# STM32U3B5 register map
File version: 1.0
CPU: CM33 r0p1, little endian, MPU, FPU, 4 interrupt priority bits
Registers are 32-bit, read-write, reset 0x0 unless marked. A register's access mark holds for its fields unless they carry their own. Offsets are from the block's base; [hi:lo] are bit positions; {n}, {i} and the like mark numbered series; 'fields as' and 'values as' point back to an identical list.

## GPDMA1 (part 2 of 2)
Base 0x40020000
Same registers: SEC_GPDMA1 0x50020000
{0xA0+0x80*i} GPDMA_C{i}DAR (i=0..11) — GPDMA channel {i} destination address register
  [31:0] DA — This field is the pointer to the address from which the next data is written. During the channel activity, depending on the destination addressing mode (GPDMA_C{i}TR1.DINC), this field is kept fixed or incremented by the data width (GPDMA_C{i}TR1.DDW_LOG2[21:0]) after each burst destination data, reflecting the next address from which data is written. During the channel activity, this address is updated after each completed destination burst, consequently to: - the programmed destination burst; either in fixed addressing mode or in contiguous-data incremented mode. If contiguously incremented (GPDMA_C{i}TR1.DINC = 1), then the additional address offset value is the programmed burst size, as defined by GPDMA_C{i}TR1.DBL_1[5:0] and GPDMA_C{i}TR1.DDW_LOG2[1:0] - the additional destination incremented/decremented offset value as programmed by GPDMA_C{i}BR1.DDEC and GPDMA_CxTR3.DAO[12:0]. - once/if completed destination block transfer, for a channel {i} with 2D addressing capability (x=12to15), the additional block repeat destination incremented/decremented offset value as programmed by GPDMA_C{i}BR1.BRDDEC and GPDMA_CxBR2.BRDAO[15:0] In linked-list mode, after a LLI data transfer is completed, this register is automatically updated by the GPDMA from the memory, provided the LLI is set with GPDMA_C{i}LLR.UDA = 1. Note: A destination address must be aligned with the programmed data width of a destination burst (DA[2:0] versus GPDMA_C{i}TR1.DDW_LOG2[1:0]). Else, a user setting error is reported and no transfer is issued.
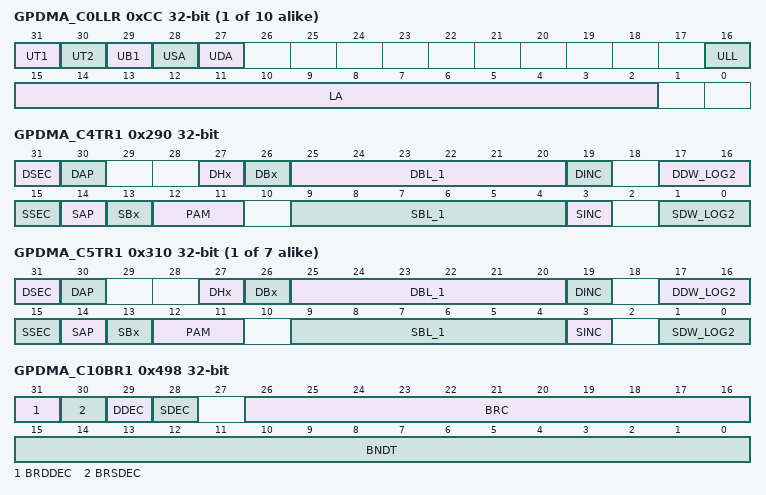
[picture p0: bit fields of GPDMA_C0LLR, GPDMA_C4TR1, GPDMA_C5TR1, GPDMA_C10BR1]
{0xCC+0x80*i} GPDMA_C{i}LLR (i=0..9) — GPDMA channel {i} linked-list address register
  [31] UT1 — This bit controls the update of GPDMA_C{i}TR1 from the memory during the link transfer. 0: no GPDMA_C{i}TR1 update 1: GPDMA_C{i}TR1 update
    0=no GPDMA_C{i}TR1 update; 1=GPDMA_C{i}TR1 update
  [30] UT2 — This bit controls the update of GPDMA_C{i}TR2 from the memory during the link transfer. 0: no GPDMA_C{i}TR2 update 1: GPDMA_C{i}TR2 update
    0=no GPDMA_C{i}TR2 update; 1=GPDMA_C{i}TR2 update
  [29] UB1 — This bit controls the update of GPDMA_C{i}BR1 from the memory during the link transfer. If UB1 = 0 and if GPDMA_C{i}LLR is not equal to 0, the linked-list is not completed. GPDMA_C{i}BR1.BNDT[15:0] is then restored to the programmed value after data transfer is completed and before the link transfer. 0: no GPDMA_C{i}BR1 update from memory (GPDMA_C{i}BR1.BNDT[15:0] restored if any link transfer) 1: GPDMA_C{i}BR1 update
    0=no GPDMA_C{i}BR1 update from memory (GPDMA_C{i}BR1.BNDT[15:0] restored if any link transfer); 1=GPDMA_C{i}BR1 update
  [28] USA — This bit controls the update of GPDMA_CxSAR from the memory during the link transfer. 0: no GPDMA_CxSAR update 1: GPDMA_CxSAR update
    0=no GPDMA_CxSAR update; 1=GPDMA_CxSAR update
  [27] UDA — This bit is used to control the update of GPDMA_CxDAR from the memory during the link transfer. 0: no GPDMA_CxDAR update 1: GPDMA_CxDAR update
    0=no GPDMA_CxDAR update; 1=GPDMA_CxDAR update
  [16] ULL — This bit is used to control the update of GPDMA_C{i}LLR from the memory during the link transfer. 0: no GPDMA_C{i}LLR update 1: GPDMA_C{i}LLR update
    0=no GPDMA_C{i}LLR update; 1=GPDMA_C{i}LLR update
  [15:2] LA — If UT1 = UT2 = UB1 = USA = UDA = ULL = 0 and if LA[15:20] = 0, the current LLI is the last one. The channel transfer is completed without any update of the linked-list GPDMA register file. Else, this field is the pointer to the memory address offset from which the next linked-list data structure is automatically fetched from, once the data transfer is completed, in order to conditionally update the linked-list GPDMA internal register file (GPDMA_C{i}TR1, GPDMA_C{i}TR2, GPDMA_C{i}BR1, GPDMA_CxSAR, GPDMA_CxDAR and GPDMA_C{i}LLR). Note: The user must program the pointer to be 32-bit aligned. The two low-significant bits are write ignored.
0x290 GPDMA_C4TR1 — GPDMA channel 4 transfer register 1
  [31] DSEC — If GPDMA_SECCFGR.SEC4 = 1 and the access is secure: This is a secure register bit. This bit can only be read by a secure software. This bit must be written by a secure software when GPDMA_SECCFGR.SEC4 = 1. A secure write is ignored when GPDMA_SECCFGR.SEC4 = 0. When GPDMA_SECCFGR.SEC4 is deasserted, this DSEC bit is also deasserted by hardware (on a secure reconfiguration of the channel as non-secure), and the GPDMA transfer to the destination is non-secure. 0: GPDMA transfer non-secure 1: GPDMA transfer secure
    0=GPDMA transfer non-secure; 1=GPDMA transfer secure
  [30] DAP — This bit is used to allocate the master port for the destination transfer 0: port 0 (AHB) allocated 1: port 1 (AHB) allocated Note: This bit must be written when EN = 0. This bit is read-only when EN = 1.
    0=port 0 (AHB) allocated; 1=port 1 (AHB) allocated
  [27] DHx — If the destination data size is shorter than a word, this bit is ignored. If the destination data size is a word: 0: no halfword-based exchanged within word 1: the two consecutive (post PAM) half-words are exchanged in each destination word.
    0=no halfword-based exchanged within word; 1=the two consecutive (post PAM) half-words are exchanged in each destination word
  [26] DBx — If the destination data size is a byte, this bit is ignored. If the destination data size is not a byte: 0: no byte-based exchange within half-word 1: the two consecutive (post PAM) bytes are exchanged in each destination half-word.
    0=no byte-based exchange within half-word; 1=the two consecutive (post PAM) bytes are exchanged in each destination half-word
  [25:20] DBL_1 — The burst length unit is one data named beat within a burst. If DBL_1[5:0] = 0, the burst can be named as single. Each data/beat has a width defined by the destination data width DDW_LOG2[1:0]. Note: If a burst transfer crossed a 1-Kbyte address boundary on a AHB transfer, the GPDMA modifies and shortens the programmed burst into singles or bursts of lower length, to be compliant with the AHB protocol. +: If a burst transfer is of length greater than the FIFO size of the channel 4, the GPDMA modifies and shortens the programmed burst into singles or bursts of lower length, to be compliant with the FIFO size. Transfer performance is lower, with GPDMA re-arbitration between effective and lower singles/bursts, but the data integrity is guaranteed.
  [19] DINC — The destination address, pointed by GPDMA_CxDAR, is kept constant after a burst beat/single transfer, or is incremented by the offset value corresponding to a contiguous data after a burst beat/single transfer. 0: fixed burst 1: contiguously incremented burst
    0=fixed burst; 1=contiguously incremented burst
  [17:16] DDW_LOG2 — None 00: byte 01: half-word (2 bytes) 10: word (4 bytes) 11: user setting error reported and no transfer issued Note: Setting a 8-byte data width causes a user setting error to be reported and none transfer is issued. +: A destination burst transfer must have an aligned address with its data width (start address GPDMA_CxDAR[2:0] and address offset GPDMA_CxTR3.DAO[2:0], versus DDW_LOG2[1:0]). Otherwise a user setting error is reported and no transfer is issued.
    0=byte; 1=half-word (2 bytes); 2=word (4 bytes); 3=user setting error reported and no transfer issued
  [15] SSEC — If GPDMA_SECCFGR.SEC4 = 1 and the access is secure: This is a secure register bit. This bit can only be read by a secure software. This bit must be written by a secure software when GPDMA_SECCFGR.SEC4 = 1. A secure write is ignored when GPDMA_SECCFGR.SEC4 = 0. When GPDMA_SECCFGR.SEC4 is deasserted, this SSEC bit is also deasserted by hardware (on a secure reconfiguration of the channel as non-secure), and the GPDMA transfer from the source is non-secure. 0: GPDMA transfer non-secure 1: GPDMA transfer secure
    0=GPDMA transfer non-secure; 1=GPDMA transfer secure
  [14] SAP — This bit is used to allocate the master port for the source transfer 0: port 0 (AHB) allocated 1: port 1 (AHB) allocated Note: This bit must be written when EN = 0. This bit is read-only when EN = 1.
    0=port 0 (AHB) allocated; 1=port 1 (AHB) allocated
  [13] SBx — If the source data width is shorter than a word, this bit is ignored. If the source data width is a word: 0: no byte-based exchange within the unaligned half-word of each source word 1: the two consecutive bytes within the unaligned half-word of each source word are exchanged.
    0=no byte-based exchange within the unaligned half-word of each source word; 1=the two consecutive bytes within the unaligned half-word of each source word are exchanged
  [12:11] PAM — If DDW_LOG2[1:0] = SDW_LOG2[1:0]: if the data width of a burst destination transfer is equal to the data width of a burst source transfer, these bits are ignored..
    0=B_0x0_COND1 (COND1 is [PAM_1] source data is transferred as right aligned, padded with 0s up to the destination data width); 1=B_0x1_COND1 (COND1 is [PAM_1] source data is transferred as right aligned, sign extended up to the destination data width); 2=B_0x2_COND1 (COND1 is [PAM_1] successive source data are FIFO queued and packed at the destination data width, in a left (LSB) to right (MSB) order (named little endian), before a destination transfer); 3=B_0x3_COND1 (COND1 is [PAM_1] successive source data are FIFO queued and packed at the destination data width, in a left (LSB) to right (MSB) order (named little endian), before a destination transfer)
  [9:4] SBL_1 — The burst length unit is one data named beat within a burst. If SBL_1[5:0] = 0, the burst can be named as single. Each data/beat has a width defined by the destination data width SDW_LOG2[1:0]. Note: If a burst transfer crossed a 1-Kbyte address boundary on a AHB transfer, the GPDMA modifies and shortens the programmed burst into singles or bursts of lower length, to be compliant with the AHB protocol. +: If a burst transfer is of length greater than the FIFO size of the channel 4, the GPDMA modifies and shortens the programmed burst into singles or bursts of lower length, to be compliant with the FIFO size. Transfer performance is lower, with GPDMA re-arbitration between effective and lower singles/bursts, but the data integrity is guaranteed.
  [3] SINC — The source address, pointed by GPDMA_CxSAR, is kept constant after a burst beat/single transfer or is incremented by the offset value corresponding to a contiguous data after a burst beat/single transfer. 0: fixed burst 1: contiguously incremented burst
    0=fixed burst; 1=contiguously incremented burst
  [1:0] SDW_LOG2 — None 00: byte 01: half-word (2 bytes) 10: word (4 bytes) 11: user setting error reported and no transfer issued Note: Setting a 8-byte data width causes a user setting error to be reported and no transfer is issued. +: A source block size must be a multiple of the source data width (GPDMA_C4BR1.BNDT[2:0] versus SDW_LOG2[1:0]). Otherwise, a user setting error is reported and no transfer is issued. +: A source burst transfer must have an aligned address with its data width (start address GPDMA_CxSAR[2:0] versus SDW_LOG2[1:0]). Otherwise, a user setting error is reported and none transfer is issued.
    values as DDW_LOG2
{0x90+0x80*i} GPDMA_C{i}TR1 (i=5..11) — GPDMA channel {i} transfer register 1
  [31] DSEC — If GPDMA_SECCFGR.SEC{i} = 1 and the access is secure: This is a secure register bit. This bit can only be read by a secure software. This bit must be written by a secure software when GPDMA_SECCFGR.SEC{i} = 1. A secure write is ignored when GPDMA_SECCFGR.SEC{i} = 0. When GPDMA_SECCFGR.SEC{i} is deasserted, this DSEC bit is also deasserted by hardware (on a secure reconfiguration of the channel as non-secure), and the GPDMA transfer to the destination is non-secure. 0: GPDMA transfer non-secure 1: GPDMA transfer secure
    0=GPDMA transfer non-secure; 1=GPDMA transfer secure
  [30] DAP — This bit is used to allocate the master port for the destination transfer 0: port 0 (AHB) allocated 1: port 1 (AHB) allocated Note: This bit must be written when EN = 0. This bit is read-only when EN = 1.
    0=port 0 (AHB) allocated; 1=port 1 (AHB) allocated
  [27] DHx — If the destination data size is shorter than a word, this bit is ignored. If the destination data size is a word: 0: no halfword-based exchanged within word 1: the two consecutive (post PAM) half-words are exchanged in each destination word.
    values as GPDMA_C4TR1.DHx
  [26] DBx — If the destination data size is a byte, this bit is ignored. If the destination data size is not a byte: 0: no byte-based exchange within half-word 1: the two consecutive (post PAM) bytes are exchanged in each destination half-word.
    values as GPDMA_C4TR1.DBx
  [25:20] DBL_1 — The burst length unit is one data named beat within a burst. If DBL_1[5:0] = 0, the burst can be named as single. Each data/beat has a width defined by the destination data width DDW_LOG2[1:0]. Note: If a burst transfer crossed a 1-Kbyte address boundary on a AHB transfer, the GPDMA modifies and shortens the programmed burst into singles or bursts of lower length, to be compliant with the AHB protocol. +: If a burst transfer is of length greater than the FIFO size of the channel {i}, the GPDMA modifies and shortens the programmed burst into singles or bursts of lower length, to be compliant with the FIFO size. Transfer performance is lower, with GPDMA re-arbitration between effective and lower singles/bursts, but the data integrity is guaranteed.
  [19] DINC — The destination address, pointed by GPDMA_CxDAR, is kept constant after a burst beat/single transfer, or is incremented by the offset value corresponding to a contiguous data after a burst beat/single transfer. 0: fixed burst 1: contiguously incremented burst
    0=fixed burst; 1=contiguously incremented burst
  [17:16] DDW_LOG2 — None 00: byte 01: half-word (2 bytes) 10: word (4 bytes) 11: user setting error reported and no transfer issued Note: Setting a 8-byte data width causes a user setting error to be reported and none transfer is issued. +: A destination burst transfer must have an aligned address with its data width (start address GPDMA_CxDAR[2:0] and address offset GPDMA_CxTR3.DAO[2:0], versus DDW_LOG2[1:0]). Otherwise a user setting error is reported and no transfer is issued.
    values as GPDMA_C4TR1.DDW_LOG2
  [15] SSEC — If GPDMA_SECCFGR.SEC{i} = 1 and the access is secure: This is a secure register bit. This bit can only be read by a secure software. This bit must be written by a secure software when GPDMA_SECCFGR.SEC{i} = 1. A secure write is ignored when GPDMA_SECCFGR.SEC{i} = 0. When GPDMA_SECCFGR.SEC{i} is deasserted, this SSEC bit is also deasserted by hardware (on a secure reconfiguration of the channel as non-secure), and the GPDMA transfer from the source is non-secure. 0: GPDMA transfer non-secure 1: GPDMA transfer secure
    0=GPDMA transfer non-secure; 1=GPDMA transfer secure
  [14] SAP — This bit is used to allocate the master port for the source transfer 0: port 0 (AHB) allocated 1: port 1 (AHB) allocated Note: This bit must be written when EN = 0. This bit is read-only when EN = 1.
    0=port 0 (AHB) allocated; 1=port 1 (AHB) allocated
  [13] SBx — If the source data width is shorter than a word, this bit is ignored. If the source data width is a word: 0: no byte-based exchange within the unaligned half-word of each source word 1: the two consecutive bytes within the unaligned half-word of each source word are exchanged.
    values as GPDMA_C4TR1.SBx
  [12:11] PAM — If DDW_LOG2[1:0] = SDW_LOG2[1:0]: if the data width of a burst destination transfer is equal to the data width of a burst source transfer, these bits are ignored.
    values as GPDMA_C4TR1.PAM
  [9:4] SBL_1 — The burst length unit is one data named beat within a burst. If SBL_1[5:0] = 0, the burst can be named as single. Each data/beat has a width defined by the destination data width SDW_LOG2[1:0]. Note: If a burst transfer crossed a 1-Kbyte address boundary on a AHB transfer, the GPDMA modifies and shortens the programmed burst into singles or bursts of lower length, to be compliant with the AHB protocol. +: If a burst transfer is of length greater than the FIFO size of the channel {i}, the GPDMA modifies and shortens the programmed burst into singles or bursts of lower length, to be compliant with the FIFO size. Transfer performance is lower, with GPDMA re-arbitration between effective and lower singles/bursts, but the data integrity is guaranteed.
  [3] SINC — The source address, pointed by GPDMA_CxSAR, is kept constant after a burst beat/single transfer or is incremented by the offset value corresponding to a contiguous data after a burst beat/single transfer. 0: fixed burst 1: contiguously incremented burst
    0=fixed burst; 1=contiguously incremented burst
  [1:0] SDW_LOG2 — None 00: byte 01: half-word (2 bytes) 10: word (4 bytes) 11: user setting error reported and no transfer issued Note: Setting a 8-byte data width causes a user setting error to be reported and no transfer is issued. +: A source block size must be a multiple of the source data width (GPDMA_C{i}BR1.BNDT[2:0] versus SDW_LOG2[1:0]). Otherwise, a user setting error is reported and no transfer is issued. +: A source burst transfer must have an aligned address with its data width (start address GPDMA_CxSAR[2:0] versus SDW_LOG2[1:0]). Otherwise, a user setting error is reported and none transfer is issued.
    values as GPDMA_C4TR1.DDW_LOG2
0x498 GPDMA_C10BR1 (alternate view of GPDMA_C8BR1) — GPDMA channel 10 block register 1
  [31] BRDDEC — None 0: at the end of a block transfer, the GPDMA_C10DAR register is updated by adding the programmed offset GPDMA_C10BR2.BRDAO to the current GPDMA_C10DAR value (current destination address) 1: at the end of a block transfer, the GPDMA_C10DAR register is updated by subtracting the programmed offset GPDMA_C10BR2.BRDAO from the current GPDMA_C10DAR value (current destination address) Note: On top of this increment/decrement (depending on BRDDEC), GPDMA_C10DAR is in the same time also updated by the increment/decrement (depending on DDEC) of the GPDMA_C10TR3.DAO value, as it is usually done at the end of each programmed bursttransfer.
    0=at the end of a block transfer, the GPDMA_C10DAR register is updated by adding the programmed offset GPDMA_C10BR2.BRDAO to the current GPDMA_C10DAR value (current destination address); 1=at the end of a block transfer, the GPDMA_C10DAR register is updated by subtracting the programmed offset GPDMA_C10BR2.BRDAO from the current GPDMA_C10DAR value (current destination address)
  [30] BRSDEC — None 0: at the end of a block transfer, the GPDMA_C10SAR register is updated by adding the programmed offset GPDMA_C10BR2.BRSAO to the current GPDMA_C10SAR value (current source address) 1: at the end of a block transfer, the GPDMA_C10SAR register is updated by subtracting the programmed offset GPDMA_C10BR2.BRSAO from the current GPDMA_C10SAR value (current source address) Note: On top of this increment/decrement (depending on BRSDEC), GPDMA_C10SAR is in the same time also updated by the increment/decrement (depending on SDEC) of the GPDMA_C10TR3.SAO value, as it is done after any programmed burst transfer.
    0=at the end of a block transfer, the GPDMA_C10SAR register is updated by adding the programmed offset GPDMA_C10BR2.BRSAO to the current GPDMA_C10SAR value (current source address); 1=at the end of a block transfer, the GPDMA_C10SAR register is updated by subtracting the programmed offset GPDMA_C10BR2.BRSAO from the current GPDMA_C10SAR value (current source address)
  [29] DDEC — None 0: At the end of a programmed burst transfer to the destination, the GPDMA_C10DAR register is updated by adding the programmed offset GPDMA_C10TR3.DAO to the current GPDMA_C10DAR value (current destination address) 1: At the end of a programmed burst transfer to the destination, the GPDMA_C10DAR register is updated by subtracting the programmed offset GPDMA_C10TR3.DAO to the current GPDMA_C10DAR value (current destination address)
    0=At the end of a programmed burst transfer to the destination, the GPDMA_C10DAR register is updated by adding the programmed offset GPDMA_C10TR3.DAO to the current GPDMA_C10DAR value (current destination address); 1=At the end of a programmed burst transfer to the destination, the GPDMA_C10DAR register is updated by subtracting the programmed offset GPDMA_C10TR3.DAO to the current GPDMA_C10DAR value (current destination address)
  [28] SDEC — None 0: At the end of a programmed burst transfer from the source, the GPDMA_C10SAR register is updated by adding the programmed offset GPDMA_C10TR3.SAO to the current GPDMA_C10SAR value (current source address) 1: At the end of a programmed burst transfer from the source, the GPDMA_C10SAR register is updated by subtracting the programmed offset GPDMA_C10TR3.SAO to the current GPDMA_C10SAR value (current source address)
    0=At the end of a programmed burst transfer from the source, the GPDMA_C10SAR register is updated by adding the programmed offset GPDMA_C10TR3.SAO to the current GPDMA_C10SAR value (current source address); 1=At the end of a programmed burst transfer from the source, the GPDMA_C10SAR register is updated by subtracting the programmed offset GPDMA_C10TR3.SAO to the current GPDMA_C10SAR value (current source address)
  [26:16] BRC — This field contains the number of repetitions of the current block (0 to 2047). When the channel is enabled, this field becomes read-only. After decrements, this field indicates the remaining number of blocks, excluding the current one. This counter is hardware decremented for each completed block transfer. Once the last block transfer is completed (BRC[10:0] = BNDT[15:0] = 0): - If GPDMA_C10LLR.UB1 = 1, all GPDMA_C10BR1 fields are updated by the next LLI in the memory. - If GPDMA_C10LLR.UB1 = 0 and if there is at least one not null Uxx update bit, this field is internally restored to the programmed value. - if all GPDMA_C10LLR.Uxx = 0 and if GPDMA_C10LLR.LA[15:0] is not equal to 0, this field is internally restored to the programmed value (infinite/continuous last LLI). - if GPDMA_C10LL R = 0, this field is kept as zero following the last LLI and data transfer.
  [15:0] BNDT — Block size transferred from the source. When the channel is enabled, this field becomes read-only and is decremented, indicating the remaining number of data items in the current source block to be transferred. BNDT[15:0] is programmed in number of bytes, maximum source block size is 64 Kbytes -1. Once the last data transfer is completed (BNDT[15:0] = 0): - if GPDMA_C10LLR.UB1 = 1, this field is updated by the LLI in the memory. - if GPDMA_C10LLR.UB1 = 0 and if there is at least one not null Uxx update bit, this field is internally restored to the programmed value. - if all GPDMA_C10LLR.Uxx = 0 and if GPDMA_C10LLR.LA[15:0] is not equal to 0, this field is internally restored to the programmed value (infinite/continuous last LLI). - if GPDMA_C10LLR = 0, this field is kept as zero following the last LLI data transfer. Note: A non-null source block size must be a multiple of the source data width (BNDT[2:0] versus GPDMA_C10TR1.SDW_LOG2[1:0]). Else a user setting error is reported and no transfer is issued. +: When configured in packing mode (GPDMA_C10TR1.PAM[1] = 1 and destination data width different from source data width), a non-null source block size must be a multiple of the destination data width (BNDT[2:0] versus GPDMA_C{x}TR1.DDW_LOG2[1:0]). Else a user setting error is reported and no transfer is issued.
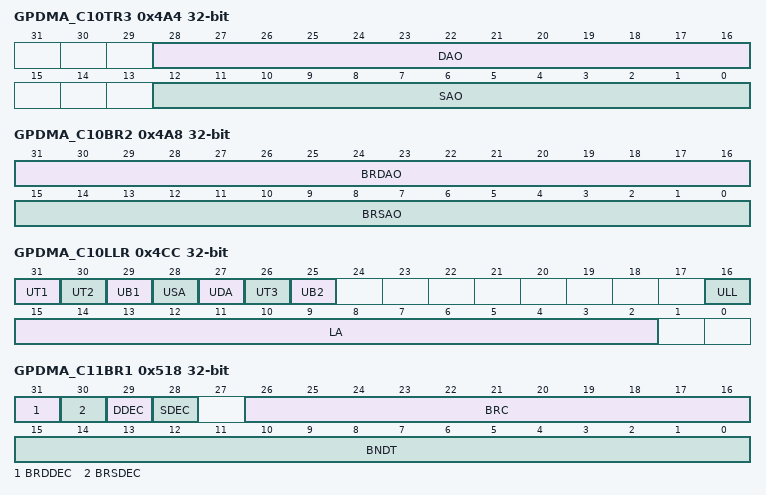
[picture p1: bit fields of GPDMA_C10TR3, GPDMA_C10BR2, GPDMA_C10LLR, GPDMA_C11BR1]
0x4A4 GPDMA_C10TR3 — GPDMA channel 10 transfer register 3
  [28:16] DAO — The destination address, pointed by GPDMA_CxDAR, is incremented or decremented (depending on GPDMA_C10BR1.DDEC) by this offset DAO[12:0] for each programmed destination burst. This offset is not including and is added to the programmed burst size when the completed burst is addressed in incremented mode (GPDMA_C10TR1.DINC = 1). Note: A destination address offset must be aligned with the programmed data width of a destination burst (DAO[2:0] versus GPDMA_C10TR1.DDW_LOG2[1:0]). Else, a user setting error is reported and no transfer is issued.
  [12:0] SAO — The source address, pointed by GPDMA_CxSAR, is incremented or decremented (depending on GPDMA_C10BR1.SDEC) by this offset SAO[12:0] for each programmed source burst. This offset is not including and is added to the programmed burst size when the completed burst is addressed in incremented mode (GPDMA_C10TR1.SINC = 1). Note: A source address offset must be aligned with the programmed data width of a source burst (SAO[2:0] versus GPDMA_C10TR1.SDW_LOG2[1:0]). Else a user setting error is reported and none transfer is issued. +: When the source block size is not a multiple of the destination burst size and is a multiple of the source data width, then the last programmed source burst is not completed and is internally shorten to match the block size. In this case, the additional GPDMA_CxTR3.SAO[12:0] is not applied.
0x4A8 GPDMA_C10BR2 — GPDMA channel 10 block register 2
  [31:16] BRDAO — For a channel with 2D addressing capability, this field is used to update (by addition or subtraction depending on GPDMA_C10BR1.BRDDEC) the current destination address (GPDMA_CxDAR) at the end of a block transfer. Note: A block repeated destination address offset must be aligned with the programmed data width of a destination burst (BRDAO[2:0] versus GPDMA_C10TR1.DDW_LOG2[1:0]). Else a user setting error is reported and no transfer is issued. +: BRDAO[15:0] must be set to 0 in peripheral flow-control mode (ifGPDMA_C10TR2.PFREQ = 1).
  [15:0] BRSAO — For a channel with 2D addressing capability, this field is used to update (by addition or subtraction depending on GPDMA_C10BR1.BRSDEC) the current source address (GPDMA_CxSAR) at the end of a block transfer. Note: A block repeated source address offset must be aligned with the programmed data width of a source burst (BRSAO[2:0] versus GPDMA_C10TR1.SDW_LOG2[1:0]). Else a user setting error is reported and no transfer is issued. +: BRSAO[15:0] must be set to 0 in peripheral flow-control mode (ifGPDMA_C10TR2.PFREQ = 1).
0x4CC GPDMA_C10LLR (alternate view of GPDMA_C8LLR) — GPDMA channel 10 linked-list address register
  [31] UT1 — This bit controls the update of GPDMA_C10TR1 from the memory during the link transfer. 0: no GPDMA_C10TR1 update 1: GPDMA_C10TR1 update
    0=no GPDMA_C10TR1 update; 1=GPDMA_C10TR1 update
  [30] UT2 — This bit controls the update of GPDMA_C10TR2 from the memory during the link transfer. 0: no GPDMA_C10TR2 update 1: GPDMA_C10TR2 update
    0=no GPDMA_C10TR2 update; 1=GPDMA_C10TR2 update
  [29] UB1 — This bit controls the update of GPDMA_C10BR1 from the memory during the link transfer. If UB1 = 0 and if GPDMA_C10LLR is not equal to 0, the linked-list is not completed. GPDMA_C10BR1.BNDT[15:0] is then restored to the programmed value after data transfer is completed and before the link transfer. 0: no GPDMA_C10BR1 update from memory (GPDMA_C10BR1.BNDT[15:0] restored if any link transfer) 1: GPDMA_C10BR1 update
    0=no GPDMA_C10BR1 update from memory (GPDMA_C10BR1.BNDT[15:0] restored if any link transfer); 1=GPDMA_C10BR1 update
  [28] USA — This bit controls the update of GPDMA_CxSAR from the memory during the link transfer. 0: no GPDMA_CxSAR update 1: GPDMA_CxSAR update
    0=no GPDMA_CxSAR update; 1=GPDMA_CxSAR update
  [27] UDA — This bit is used to control the update of GPDMA_CxDAR from the memory during the link transfer. 0: no GPDMA_CxDAR update 1: GPDMA_CxDAR update
    0=no GPDMA_CxDAR update; 1=GPDMA_CxDAR update
  [26] UT3 — This bit controls the update of GPDMA_CxTR3 from the memory during the link transfer. 0: no GPDMA_CxTR3 update 1: GPDMA_CxTR3 update
    0=no GPDMA_CxTR3 update; 1=GPDMA_CxTR3 update
  [25] UB2 — This bit controls the update of GPDMA_CxBR2 from the memory during the link transfer. 0: no GPDMA_CxBR2 update 1: GPDMA_CxBR2 update
    0=no GPDMA_CxBR2 update; 1=GPDMA_CxBR2 update
  [16] ULL — This bit is used to control the update of GPDMA_C10LLR from the memory during the link transfer. 0: no GPDMA_C10LLR update 1: GPDMA_C10LLR update
    0=no GPDMA_C10LLR update; 1=GPDMA_C10LLR update
  [15:2] LA — If UT1 = UT2 = UB1 = USA = UDA = ULL = 0 and if LA[15:20] = 0, the current LLI is the last one. The channel transfer is completed without any update of the linked-list GPDMA register file. Else, this field is the pointer to the memory address offset from which the next linked-list data structure is automatically fetched from, once the data transfer is completed, in order to conditionally update the linked-list GPDMA internal register file (GPDMA_C10TR1, GPDMA_C10TR2, GPDMA_C10BR1, GPDMA_CxSAR, GPDMA_CxDAR and GPDMA_C10LLR). Note: The user must program the pointer to be 32-bit aligned. The two low-significant bits are write ignored.
0x518 GPDMA_C11BR1 (alternate view of GPDMA_C9BR1) — GPDMA channel 11 block register 1
  [31] BRDDEC — None 0: at the end of a block transfer, the GPDMA_C11DAR register is updated by adding the programmed offset GPDMA_C11BR2.BRDAO to the current GPDMA_C11DAR value (current destination address) 1: at the end of a block transfer, the GPDMA_C11DAR register is updated by subtracting the programmed offset GPDMA_C11BR2.BRDAO from the current GPDMA_C11DAR value (current destination address) Note: On top of this increment/decrement (depending on BRDDEC), GPDMA_C11DAR is in the same time also updated by the increment/decrement (depending on DDEC) of the GPDMA_C11TR3.DAO value, as it is usually done at the end of each programmed bursttransfer.
    0=at the end of a block transfer, the GPDMA_C11DAR register is updated by adding the programmed offset GPDMA_C11BR2.BRDAO to the current GPDMA_C11DAR value (current destination address); 1=at the end of a block transfer, the GPDMA_C11DAR register is updated by subtracting the programmed offset GPDMA_C11BR2.BRDAO from the current GPDMA_C11DAR value (current destination address)
  [30] BRSDEC — None 0: at the end of a block transfer, the GPDMA_C11SAR register is updated by adding the programmed offset GPDMA_C11BR2.BRSAO to the current GPDMA_C11SAR value (current source address) 1: at the end of a block transfer, the GPDMA_C11SAR register is updated by subtracting the programmed offset GPDMA_C11BR2.BRSAO from the current GPDMA_C11SAR value (current source address) Note: On top of this increment/decrement (depending on BRSDEC), GPDMA_C11SAR is in the same time also updated by the increment/decrement (depending on SDEC) of the GPDMA_C11TR3.SAO value, as it is done after any programmed burst transfer.
    0=at the end of a block transfer, the GPDMA_C11SAR register is updated by adding the programmed offset GPDMA_C11BR2.BRSAO to the current GPDMA_C11SAR value (current source address); 1=at the end of a block transfer, the GPDMA_C11SAR register is updated by subtracting the programmed offset GPDMA_C11BR2.BRSAO from the current GPDMA_C11SAR value (current source address)
  [29] DDEC — None 0: At the end of a programmed burst transfer to the destination, the GPDMA_C11DAR register is updated by adding the programmed offset GPDMA_C11TR3.DAO to the current GPDMA_C11DAR value (current destination address) 1: At the end of a programmed burst transfer to the destination, the GPDMA_C11DAR register is updated by subtracting the programmed offset GPDMA_C11TR3.DAO to the current GPDMA_C11DAR value (current destination address)
    0=At the end of a programmed burst transfer to the destination, the GPDMA_C11DAR register is updated by adding the programmed offset GPDMA_C11TR3.DAO to the current GPDMA_C11DAR value (current destination address); 1=At the end of a programmed burst transfer to the destination, the GPDMA_C11DAR register is updated by subtracting the programmed offset GPDMA_C11TR3.DAO to the current GPDMA_C11DAR value (current destination address)
  [28] SDEC — None 0: At the end of a programmed burst transfer from the source, the GPDMA_C11SAR register is updated by adding the programmed offset GPDMA_C11TR3.SAO to the current GPDMA_C11SAR value (current source address) 1: At the end of a programmed burst transfer from the source, the GPDMA_C11SAR register is updated by subtracting the programmed offset GPDMA_C11TR3.SAO to the current GPDMA_C11SAR value (current source address)
    0=At the end of a programmed burst transfer from the source, the GPDMA_C11SAR register is updated by adding the programmed offset GPDMA_C11TR3.SAO to the current GPDMA_C11SAR value (current source address); 1=At the end of a programmed burst transfer from the source, the GPDMA_C11SAR register is updated by subtracting the programmed offset GPDMA_C11TR3.SAO to the current GPDMA_C11SAR value (current source address)
  [26:16] BRC — This field contains the number of repetitions of the current block (0 to 2047). When the channel is enabled, this field becomes read-only. After decrements, this field indicates the remaining number of blocks, excluding the current one. This counter is hardware decremented for each completed block transfer. Once the last block transfer is completed (BRC[10:0] = BNDT[15:0] = 0): - If GPDMA_C11LLR.UB1 = 1, all GPDMA_C11BR1 fields are updated by the next LLI in the memory. - If GPDMA_C11LLR.UB1 = 0 and if there is at least one not null Uxx update bit, this field is internally restored to the programmed value. - if all GPDMA_C11LLR.Uxx = 0 and if GPDMA_C11LLR.LA[15:0] is not equal to 0, this field is internally restored to the programmed value (infinite/continuous last LLI). - if GPDMA_C11LL R = 0, this field is kept as zero following the last LLI and data transfer.
  [15:0] BNDT — Block size transferred from the source. When the channel is enabled, this field becomes read-only and is decremented, indicating the remaining number of data items in the current source block to be transferred. BNDT[15:0] is programmed in number of bytes, maximum source block size is 64 Kbytes -1. Once the last data transfer is completed (BNDT[15:0] = 0): - if GPDMA_C11LLR.UB1 = 1, this field is updated by the LLI in the memory. - if GPDMA_C11LLR.UB1 = 0 and if there is at least one not null Uxx update bit, this field is internally restored to the programmed value. - if all GPDMA_C11LLR.Uxx = 0 and if GPDMA_C11LLR.LA[15:0] is not equal to 0, this field is internally restored to the programmed value (infinite/continuous last LLI). - if GPDMA_C11LLR = 0, this field is kept as zero following the last LLI data transfer. Note: A non-null source block size must be a multiple of the source data width (BNDT[2:0] versus GPDMA_C11TR1.SDW_LOG2[1:0]). Else a user setting error is reported and no transfer is issued. +: When configured in packing mode (GPDMA_C11TR1.PAM[1] = 1 and destination data width different from source data width), a non-null source block size must be a multiple of the destination data width (BNDT[2:0] versus GPDMA_C{x}TR1.DDW_LOG2[1:0]). Else a user setting error is reported and no transfer is issued.
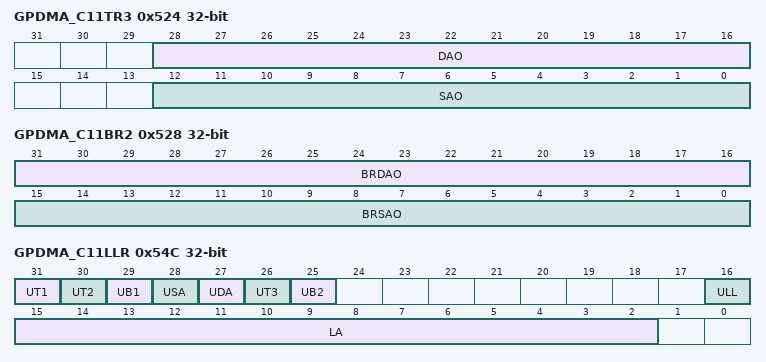
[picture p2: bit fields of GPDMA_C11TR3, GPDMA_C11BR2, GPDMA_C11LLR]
0x524 GPDMA_C11TR3 — GPDMA channel 11 transfer register 3
  [28:16] DAO — The destination address, pointed by GPDMA_CxDAR, is incremented or decremented (depending on GPDMA_C11BR1.DDEC) by this offset DAO[12:0] for each programmed destination burst. This offset is not including and is added to the programmed burst size when the completed burst is addressed in incremented mode (GPDMA_C11TR1.DINC = 1). Note: A destination address offset must be aligned with the programmed data width of a destination burst (DAO[2:0] versus GPDMA_C11TR1.DDW_LOG2[1:0]). Else, a user setting error is reported and no transfer is issued.
  [12:0] SAO — The source address, pointed by GPDMA_CxSAR, is incremented or decremented (depending on GPDMA_C11BR1.SDEC) by this offset SAO[12:0] for each programmed source burst. This offset is not including and is added to the programmed burst size when the completed burst is addressed in incremented mode (GPDMA_C11TR1.SINC = 1). Note: A source address offset must be aligned with the programmed data width of a source burst (SAO[2:0] versus GPDMA_C11TR1.SDW_LOG2[1:0]). Else a user setting error is reported and none transfer is issued. +: When the source block size is not a multiple of the destination burst size and is a multiple of the source data width, then the last programmed source burst is not completed and is internally shorten to match the block size. In this case, the additional GPDMA_CxTR3.SAO[12:0] is not applied.
0x528 GPDMA_C11BR2 — GPDMA channel 11 block register 2
  [31:16] BRDAO — For a channel with 2D addressing capability, this field is used to update (by addition or subtraction depending on GPDMA_C11BR1.BRDDEC) the current destination address (GPDMA_CxDAR) at the end of a block transfer. Note: A block repeated destination address offset must be aligned with the programmed data width of a destination burst (BRDAO[2:0] versus GPDMA_C11TR1.DDW_LOG2[1:0]). Else a user setting error is reported and no transfer is issued. +: BRDAO[15:0] must be set to 0 in peripheral flow-control mode (ifGPDMA_C11TR2.PFREQ = 1).
  [15:0] BRSAO — For a channel with 2D addressing capability, this field is used to update (by addition or subtraction depending on GPDMA_C11BR1.BRSDEC) the current source address (GPDMA_CxSAR) at the end of a block transfer. Note: A block repeated source address offset must be aligned with the programmed data width of a source burst (BRSAO[2:0] versus GPDMA_C11TR1.SDW_LOG2[1:0]). Else a user setting error is reported and no transfer is issued. +: BRSAO[15:0] must be set to 0 in peripheral flow-control mode (ifGPDMA_C11TR2.PFREQ = 1).
0x54C GPDMA_C11LLR (alternate view of GPDMA_C9LLR) — GPDMA channel 11 linked-list address register
  [31] UT1 — This bit controls the update of GPDMA_C11TR1 from the memory during the link transfer. 0: no GPDMA_C11TR1 update 1: GPDMA_C11TR1 update
    0=no GPDMA_C11TR1 update; 1=GPDMA_C11TR1 update
  [30] UT2 — This bit controls the update of GPDMA_C11TR2 from the memory during the link transfer. 0: no GPDMA_C11TR2 update 1: GPDMA_C11TR2 update
    0=no GPDMA_C11TR2 update; 1=GPDMA_C11TR2 update
  [29] UB1 — This bit controls the update of GPDMA_C11BR1 from the memory during the link transfer. If UB1 = 0 and if GPDMA_C11LLR is not equal to 0, the linked-list is not completed. GPDMA_C11BR1.BNDT[15:0] is then restored to the programmed value after data transfer is completed and before the link transfer. 0: no GPDMA_C11BR1 update from memory (GPDMA_C11BR1.BNDT[15:0] restored if any link transfer) 1: GPDMA_C11BR1 update
    0=no GPDMA_C11BR1 update from memory (GPDMA_C11BR1.BNDT[15:0] restored if any link transfer); 1=GPDMA_C11BR1 update
  [28] USA — This bit controls the update of GPDMA_CxSAR from the memory during the link transfer. 0: no GPDMA_CxSAR update 1: GPDMA_CxSAR update
    0=no GPDMA_CxSAR update; 1=GPDMA_CxSAR update
  [27] UDA — This bit is used to control the update of GPDMA_CxDAR from the memory during the link transfer. 0: no GPDMA_CxDAR update 1: GPDMA_CxDAR update
    0=no GPDMA_CxDAR update; 1=GPDMA_CxDAR update
  [26] UT3 — This bit controls the update of GPDMA_CxTR3 from the memory during the link transfer. 0: no GPDMA_CxTR3 update 1: GPDMA_CxTR3 update
    0=no GPDMA_CxTR3 update; 1=GPDMA_CxTR3 update
  [25] UB2 — This bit controls the update of GPDMA_CxBR2 from the memory during the link transfer. 0: no GPDMA_CxBR2 update 1: GPDMA_CxBR2 update
    0=no GPDMA_CxBR2 update; 1=GPDMA_CxBR2 update
  [16] ULL — This bit is used to control the update of GPDMA_C11LLR from the memory during the link transfer. 0: no GPDMA_C11LLR update 1: GPDMA_C11LLR update
    0=no GPDMA_C11LLR update; 1=GPDMA_C11LLR update
  [15:2] LA — If UT1 = UT2 = UB1 = USA = UDA = ULL = 0 and if LA[15:20] = 0, the current LLI is the last one. The channel transfer is completed without any update of the linked-list GPDMA register file. Else, this field is the pointer to the memory address offset from which the next linked-list data structure is automatically fetched from, once the data transfer is completed, in order to conditionally update the linked-list GPDMA internal register file (GPDMA_C11TR1, GPDMA_C11TR2, GPDMA_C11BR1, GPDMA_CxSAR, GPDMA_CxDAR and GPDMA_C11LLR). Note: The user must program the pointer to be 32-bit aligned. The two low-significant bits are write ignored.
